# G32R501 register map
Vendor: Geehy Semiconductor Co., Ltd.; Series: G32R5; File version: 1.0
CPU: CM55 r0p1, little endian, MPU, FPU, double-precision FPU, DSP, VTOR, 4 interrupt priority bits
Registers are 32-bit, read-write, reset 0x0 unless marked. A register's access mark holds for its fields unless they carry their own. Offsets are from the block's base; [hi:lo] are bit positions; 'fields as' and 'values as' point back to an identical list.

## COMP1 — Comparator
Base 0x40011C00
Same registers: COMP2 0x40012000, COMP3 0x40012400, COMP4 0x40012800, COMP5 0x40012C00, COMP6 0x40013000, COMP7 0x40013400
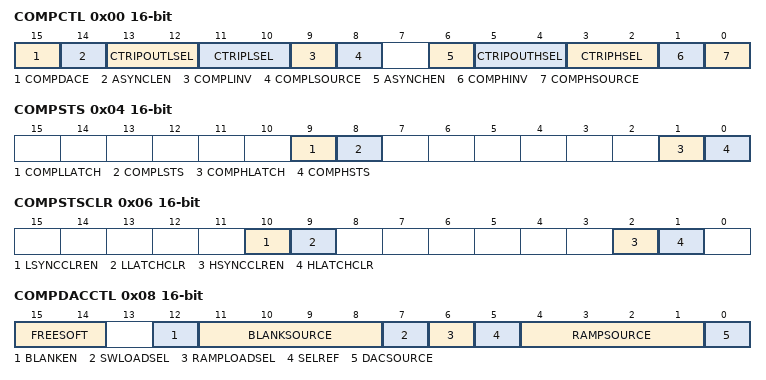
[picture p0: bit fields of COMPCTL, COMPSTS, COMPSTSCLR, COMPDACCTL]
0x00 COMPCTL 16-bit — COMP Comparator Control Register
  [15] COMPDACE — Comparator/DAC Enable
  [14] ASYNCLEN — Low Comparator Asynchronous Path Enable
  [13:12] CTRIPOUTLSEL — Low Comparator Trip Output Select
  [11:10] CTRIPLSEL — Low Comparator Trip Select
  [9] COMPLINV — Low Comparator Invert Select
  [8] COMPLSOURCE — Low Comparator Source Select
  [6] ASYNCHEN — High Comparator Asynchronous Path Enable
  [5:4] CTRIPOUTHSEL — High Comparator Trip Output Select
  [3:2] CTRIPHSEL — High Comparator Trip Select
  [1] COMPHINV — High Comparator Invert Select
  [0] COMPHSOURCE — High Comparator Source Select
0x02 COMPHYSCTL 16-bit — COMP Comparator Hysteresis Control Register
  [3:0] COMPHYS — Comparator Hysteresis Trim
0x04 COMPSTS 16-bit ro — COMP Comparator Status Register
  [9] COMPLLATCH — Low Comparator Latched Status
  [8] COMPLSTS — Low Comparator Status
  [1] COMPHLATCH — High Comparator Latched Status
  [0] COMPHSTS — High Comparator Status
0x06 COMPSTSCLR 16-bit — COMP Comparator Status Clear Register
  [10] LSYNCCLREN — Low Comparator EPWMSYNCPER Clear Enable
  [9] LLATCHCLR — Low Comparator Latched Status Clear
  [2] HSYNCCLREN — High Comparator EPWMSYNCPER Clear Enable
  [1] HLATCHCLR — High Comparator Latched Status Clear
0x08 COMPDACCTL 16-bit — COMP DAC Control Register
  [15:14] FREESOFT — Free/Soft Emulation Bits
  [12] BLANKEN — EPWMBLANK Enable
  [11:8] BLANKSOURCE — EPWMBLANK Source Select
  [7] SWLOADSEL — Software Load Select
  [6] RAMPLOADSEL — Ramp Load Select
  [5] SELREF — DAC Reference Select
  [4:1] RAMPSOURCE — Ramp Generator Source Control
  [0] DACSOURCE — DAC Source Control
0x0C DACHVALS 16-bit — COMP High DAC Value Shadow Register
  [11:0] DACVAL — DAC Value Control
0x0E DACHVALA 16-bit ro — COMP High DAC Value Active Register
  [11:0] DACVAL — DAC Value Control
0x10 RAMPMAXREFA 16-bit ro — COMP Ramp Max Reference Active Register
  [15:0] RAMPMAXREFA — Ramp maximum reference active value
0x14 RAMPMAXREFS 16-bit — COMP Ramp Max Reference Shadow Register
  [15:0] RAMPMAXREFS — Ramp maximum reference shadow value
0x18 RAMPDECVALA 16-bit ro — COMP Ramp Decrement Value Active Register
  [15:0] RAMPDECVALA — Ramp decrement value active
0x1C RAMPDECVALS 16-bit — COMP Ramp Decrement Value Shadow Register
  [15:0] RAMPDECVALS — Ramp decrement value shadow
0x20 RAMPSTS 16-bit ro — COMP Ramp Status Register
  [15:0] RAMPSTS — Ramp value
0x24 DACLVALS 16-bit — COMP Low DAC Value Shadow Register
  [11:0] DACVAL — DAC Value Control
0x26 DACLVALA 16-bit ro — COMP Low DAC Value Active Register
  [11:0] DACVAL — DAC Value Control
0x28 RAMPDLYA 16-bit ro — COMP Ramp Delay Active Register
  [12:0] DELAY — Ramp Delay Value
0x2A RAMPDLYS 16-bit — COMP Ramp Delay Shadow Register
  [12:0] DELAY — Ramp Delay Value
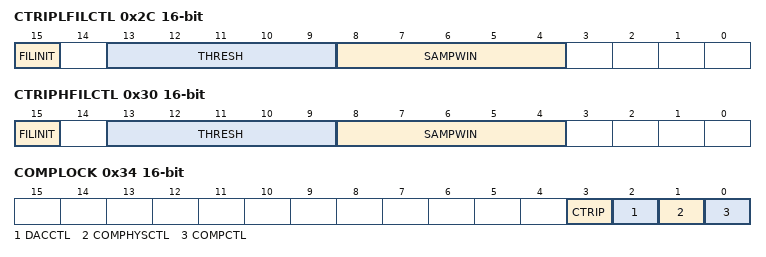
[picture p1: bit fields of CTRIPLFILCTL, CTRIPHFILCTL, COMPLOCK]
0x2C CTRIPLFILCTL 16-bit — CTRIPL Filter Control Register
  [15] FILINIT — Filter Initialization Bit
  [13:9] THRESH — Majority Voting Threshold
  [8:4] SAMPWIN — Sample Window
0x2E CTRIPLFILCLKCTL 16-bit — CTRIPL Filter Clock Control Register
  [9:0] CLKPRESCALE — Sample Clock Prescale
0x30 CTRIPHFILCTL 16-bit — CTRIPH Filter Control Register
  fields as CTRIPLFILCTL
0x32 CTRIPHFILCLKCTL 16-bit — CTRIPH Filter Clock Control Register
  [9:0] CLKPRESCALE — Sample Clock Prescale
0x34 COMPLOCK 16-bit write-once
  [3] CTRIP — CTRIP Lock
  [2] DACCTL — DACCTL Lock
  [1] COMPHYSCTL — COMPHYSCTL Lock
  [0] COMPCTL — COMPCTL Lock
